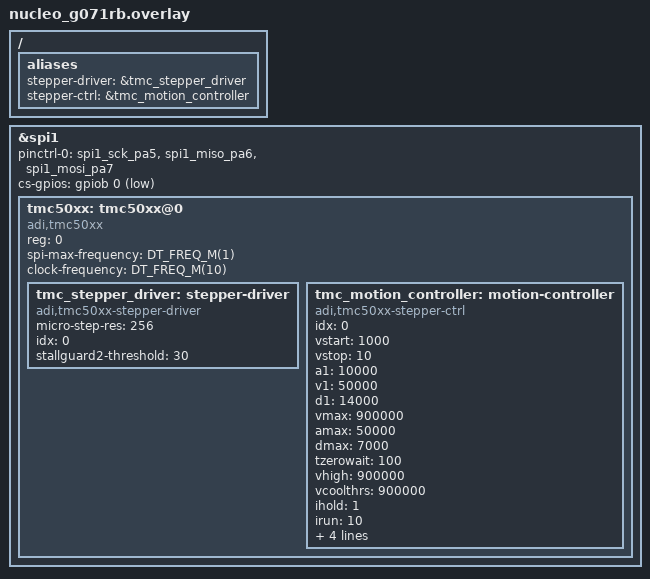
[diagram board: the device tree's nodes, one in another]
/*
 * SPDX-FileCopyrightText: Copyright (c) 2025 Dipak Shetty
 * SPDX-FileCopyrightText: Copyright (c) 2024 Jilay Sandeep Pandya
 * SPDX-License-Identifier: Apache-2.0
 */

/ {
	aliases {
		stepper-driver = &tmc_stepper_driver;
		stepper-ctrl = &tmc_motion_controller;
	};
};

&spi1 {
	pinctrl-0 = <&spi1_sck_pa5 &spi1_miso_pa6 &spi1_mosi_pa7>;
	pinctrl-names = "default";
	cs-gpios = <&gpiob 0 GPIO_ACTIVE_LOW>;
	status = "okay";

	tmc50xx: tmc50xx@0 {
		compatible = "adi,tmc50xx";
		reg = <0>;
		spi-max-frequency = <DT_FREQ_M(1)>; /* Maximum SPI bus frequency */

		clock-frequency = <DT_FREQ_M(10)>; /* Internal/External Clock frequency */

		/* common stepper controller settings */
		tmc_stepper_driver: stepper-driver {
			micro-step-res = <256>;
			idx = <0>;
			compatible = "adi,tmc50xx-stepper-driver";
			/* ADI TMC stallguard settings specific to TMC50XX */
			stallguard2-threshold = <30>;
		};

		/* ADI TMC ramp generator as well as current settings */
		tmc_motion_controller: motion-controller {
			compatible = "adi,tmc50xx-stepper-ctrl";
			idx = <0>;
			vstart = <1000>;
			vstop = <10>;
			a1 = <10000>;
			v1 = <50000>;
			d1 = <14000>;
			vmax = <900000>;
			amax = <50000>;
			dmax = <7000>;
			tzerowait = <100>;
			vhigh = <900000>;
			vcoolthrs = <900000>;
			ihold = <1>;
			irun = <10>;
			iholddelay = <1>;
			activate-stallguard2;
			stallguard-velocity-check-interval-ms = <1000>;
			stallguard-threshold-velocity = <200000>;
		};
	};
};
